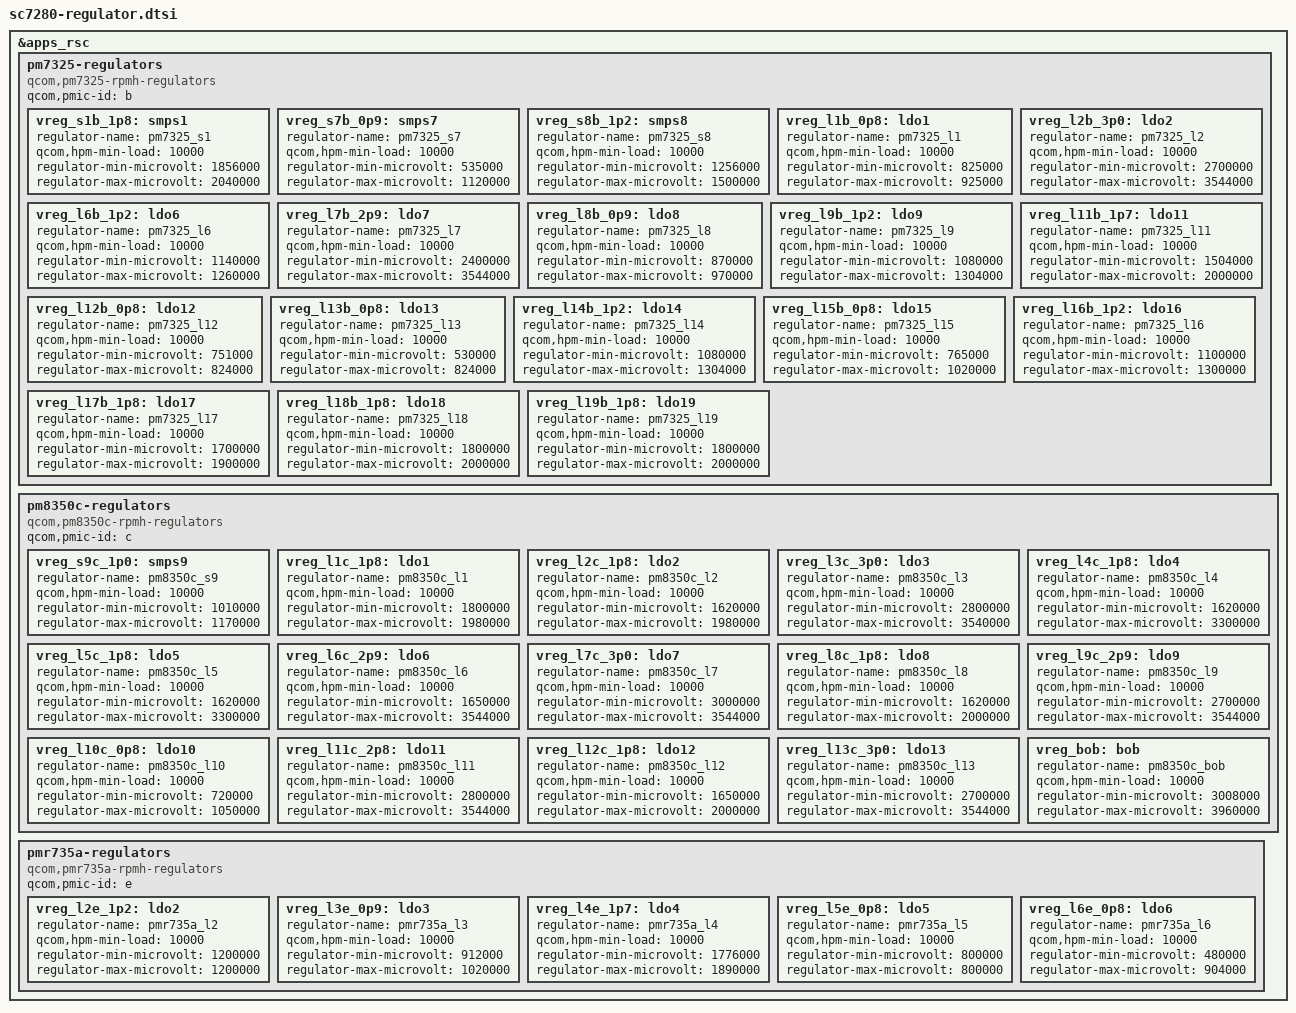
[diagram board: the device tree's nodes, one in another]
// SPDX-License-Identifier: GPL-2.0-Only
// Copyright (c) 2021, The Linux Foundation. All rights reserved.

&apps_rsc {
	pm7325-regulators {
		compatible = "qcom,pm7325-rpmh-regulators";
		qcom,pmic-id = "b";

		vreg_s1b_1p8: smps1 {
			regulator-name = "pm7325_s1";
			qcom,hpm-min-load = <10000>;
			regulator-min-microvolt = <1856000>;
			regulator-max-microvolt = <2040000>;
		};

		vreg_s7b_0p9: smps7 {
			regulator-name = "pm7325_s7";
			qcom,hpm-min-load = <10000>;
			regulator-min-microvolt = <535000>;
			regulator-max-microvolt = <1120000>;
		};

		vreg_s8b_1p2: smps8 {
			regulator-name = "pm7325_s8";
			qcom,hpm-min-load = <10000>;
			regulator-min-microvolt = <1256000>;
			regulator-max-microvolt = <1500000>;
		};

		vreg_l1b_0p8: ldo1 {
			regulator-name = "pm7325_l1";
			qcom,hpm-min-load = <10000>;
			regulator-min-microvolt = <825000>;
			regulator-max-microvolt = <925000>;
		};

		vreg_l2b_3p0: ldo2 {
			regulator-name = "pm7325_l2";
			qcom,hpm-min-load = <10000>;
			regulator-min-microvolt = <2700000>;
			regulator-max-microvolt = <3544000>;
		};

		vreg_l6b_1p2: ldo6 {
			regulator-name = "pm7325_l6";
			qcom,hpm-min-load = <10000>;
			regulator-min-microvolt = <1140000>;
			regulator-max-microvolt = <1260000>;
		};

		vreg_l7b_2p9: ldo7 {
			regulator-name = "pm7325_l7";
			qcom,hpm-min-load = <10000>;
			regulator-min-microvolt = <2400000>;
			regulator-max-microvolt = <3544000>;
		};

		vreg_l8b_0p9: ldo8 {
			regulator-name = "pm7325_l8";
			qcom,hpm-min-load = <10000>;
			regulator-min-microvolt = <870000>;
			regulator-max-microvolt = <970000>;
		};

		vreg_l9b_1p2: ldo9 {
			regulator-name = "pm7325_l9";
			qcom,hpm-min-load = <10000>;
			regulator-min-microvolt = <1080000>;
			regulator-max-microvolt = <1304000>;
		};

		vreg_l11b_1p7: ldo11 {
			regulator-name = "pm7325_l11";
			qcom,hpm-min-load = <10000>;
			regulator-min-microvolt = <1504000>;
			regulator-max-microvolt = <2000000>;
		};

		vreg_l12b_0p8: ldo12 {
			regulator-name = "pm7325_l12";
			qcom,hpm-min-load = <10000>;
			regulator-min-microvolt = <751000>;
			regulator-max-microvolt = <824000>;
		};

		vreg_l13b_0p8: ldo13 {
			regulator-name = "pm7325_l13";
			qcom,hpm-min-load = <10000>;
			regulator-min-microvolt = <530000>;
			regulator-max-microvolt = <824000>;
		};

		vreg_l14b_1p2: ldo14 {
			regulator-name = "pm7325_l14";
			qcom,hpm-min-load = <10000>;
			regulator-min-microvolt = <1080000>;
			regulator-max-microvolt = <1304000>;
		};

		vreg_l15b_0p8: ldo15 {
			regulator-name = "pm7325_l15";
			qcom,hpm-min-load = <10000>;
			regulator-min-microvolt = <765000>;
			regulator-max-microvolt = <1020000>;
		};

		vreg_l16b_1p2: ldo16 {
			regulator-name = "pm7325_l16";
			qcom,hpm-min-load = <10000>;
			regulator-min-microvolt = <1100000>;
			regulator-max-microvolt = <1300000>;
		};

		vreg_l17b_1p8: ldo17 {
			regulator-name = "pm7325_l17";
			qcom,hpm-min-load = <10000>;
			regulator-min-microvolt = <1700000>;
			regulator-max-microvolt = <1900000>;
		};

		vreg_l18b_1p8: ldo18 {
			regulator-name = "pm7325_l18";
			qcom,hpm-min-load = <10000>;
			regulator-min-microvolt = <1800000>;
			regulator-max-microvolt = <2000000>;
		};

		vreg_l19b_1p8: ldo19 {
			regulator-name = "pm7325_l19";
			qcom,hpm-min-load = <10000>;
			regulator-min-microvolt = <1800000>;
			regulator-max-microvolt = <2000000>;
		};
	};

	pm8350c-regulators {
	compatible = "qcom,pm8350c-rpmh-regulators";
	qcom,pmic-id = "c";
		vreg_s9c_1p0: smps9 {
			regulator-name = "pm8350c_s9";
			qcom,hpm-min-load = <10000>;
			regulator-min-microvolt = <1010000>;
			regulator-max-microvolt = <1170000>;
		};

		vreg_l1c_1p8: ldo1 {
			regulator-name = "pm8350c_l1";
			qcom,hpm-min-load = <10000>;
			regulator-min-microvolt = <1800000>;
			regulator-max-microvolt = <1980000>;
		};

		vreg_l2c_1p8: ldo2 {
			regulator-name = "pm8350c_l2";
			qcom,hpm-min-load = <10000>;
			regulator-min-microvolt = <1620000>;
			regulator-max-microvolt = <1980000>;
		};

		vreg_l3c_3p0: ldo3 {
			regulator-name = "pm8350c_l3";
			qcom,hpm-min-load = <10000>;
			regulator-min-microvolt = <2800000>;
			regulator-max-microvolt = <3540000>;
		};

		vreg_l4c_1p8: ldo4 {
			regulator-name = "pm8350c_l4";
			qcom,hpm-min-load = <10000>;
			regulator-min-microvolt = <1620000>;
			regulator-max-microvolt = <3300000>;
		};

		vreg_l5c_1p8: ldo5 {
			regulator-name = "pm8350c_l5";
			qcom,hpm-min-load = <10000>;
			regulator-min-microvolt = <1620000>;
			regulator-max-microvolt = <3300000>;
		};

		vreg_l6c_2p9: ldo6 {
			regulator-name = "pm8350c_l6";
			qcom,hpm-min-load = <10000>;
			regulator-min-microvolt = <1650000>;
			regulator-max-microvolt = <3544000>;
		};

		vreg_l7c_3p0: ldo7 {
			regulator-name = "pm8350c_l7";
			qcom,hpm-min-load = <10000>;
			regulator-min-microvolt = <3000000>;
			regulator-max-microvolt = <3544000>;
		};

		vreg_l8c_1p8: ldo8 {
			regulator-name = "pm8350c_l8";
			qcom,hpm-min-load = <10000>;
			regulator-min-microvolt = <1620000>;
			regulator-max-microvolt = <2000000>;
		};

		vreg_l9c_2p9: ldo9 {
			regulator-name = "pm8350c_l9";
			qcom,hpm-min-load = <10000>;
			regulator-min-microvolt = <2700000>;
			regulator-max-microvolt = <3544000>;
		};

		vreg_l10c_0p8: ldo10 {
			regulator-name = "pm8350c_l10";
			qcom,hpm-min-load = <10000>;
			regulator-min-microvolt = <720000>;
			regulator-max-microvolt = <1050000>;
		};

		vreg_l11c_2p8: ldo11 {
			regulator-name = "pm8350c_l11";
			qcom,hpm-min-load = <10000>;
			regulator-min-microvolt = <2800000>;
			regulator-max-microvolt = <3544000>;
		};

		vreg_l12c_1p8: ldo12 {
			regulator-name = "pm8350c_l12";
			qcom,hpm-min-load = <10000>;
			regulator-min-microvolt = <1650000>;
			regulator-max-microvolt = <2000000>;
		};

		vreg_l13c_3p0: ldo13 {
			regulator-name = "pm8350c_l13";
			qcom,hpm-min-load = <10000>;
			regulator-min-microvolt = <2700000>;
			regulator-max-microvolt = <3544000>;
		};

		vreg_bob: bob {
			regulator-name = "pm8350c_bob";
			qcom,hpm-min-load = <10000>;
			regulator-min-microvolt = <3008000>;
			regulator-max-microvolt = <3960000>;
		};
	};

	pmr735a-regulators {
		compatible = "qcom,pmr735a-rpmh-regulators";
		qcom,pmic-id = "e";

		vreg_l2e_1p2: ldo2 {
			regulator-name = "pmr735a_l2";
			qcom,hpm-min-load = <10000>;
			regulator-min-microvolt = <1200000>;
			regulator-max-microvolt = <1200000>;
		};

		vreg_l3e_0p9: ldo3 {
			regulator-name = "pmr735a_l3";
			qcom,hpm-min-load = <10000>;
			regulator-min-microvolt = <912000>;
			regulator-max-microvolt = <1020000>;
		};

		vreg_l4e_1p7: ldo4 {
			regulator-name = "pmr735a_l4";
			qcom,hpm-min-load = <10000>;
			regulator-min-microvolt = <1776000>;
			regulator-max-microvolt = <1890000>;
		};

		vreg_l5e_0p8: ldo5 {
			regulator-name = "pmr735a_l5";
			qcom,hpm-min-load = <10000>;
			regulator-min-microvolt = <800000>;
			regulator-max-microvolt = <800000>;
		};

		vreg_l6e_0p8: ldo6 {
			regulator-name = "pmr735a_l6";
			qcom,hpm-min-load = <10000>;
			regulator-min-microvolt = <480000>;
			regulator-max-microvolt = <904000>;
		};
	};
};
